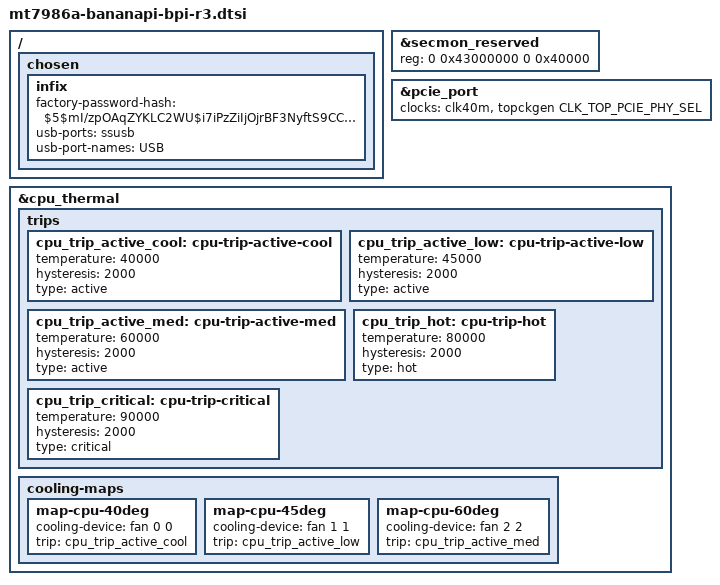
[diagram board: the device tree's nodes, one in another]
/ {
	chosen {
		infix {
			/* Default admin user password: 'admin' */
			factory-password-hash = "$5$mI/zpOAqZYKLC2WU$i7iPzZiIjOjrBF3NyftS9CCq8dfYwHwrmUK097Jca9A";
			usb-ports = <&ssusb>;
			usb-port-names = "USB";
		};
	};
};
/*
From 236317dd4e55512933dcdaec3d0b4a0824f5e5bd Mon Sep 17 00:00:00 2001
From: Shiji Yang <yangshiji66@outlook.com>
Date: Sun, 10 Aug 2025 18:11:01 +0800
Subject: [PATCH] arm64: dts: mediatek: mt7986: increase ATF reserved memory to
 256 kiB

The latest Mediatek open-source Trusted Firmware-A project has
reserved 256 KiB for BL2 and BL31. It is better to increase the
reserved memory region in the Linux kernel to protect the data.

https://github.com/openwrt/openwrt/blob/main/target/linux/mediatek/patches-6.12/199-arm64-dts-mediatek-mt7986-increase-ATF-reserved-memo.patch
*/
&secmon_reserved {
	reg = <0 0x43000000 0 0x40000>;
};
/*
 * The T-PHY's pcie-phy sub-node only claims clk40m ("ref") in the SoC
 * dtsi.  CLK_TOP_PCIE_PHY_SEL ("da_ref") is left unclaimed, so the
 * kernel's clk_disable_unused late_initcall gates it — killing the
 * PCIe REFCLK output to the endpoint mid-probe.  Wire it here so the
 * clock stays enabled while the PHY is active.
 */
&pcie_port {
	clocks = <&clk40m>, <&topckgen CLK_TOP_PCIE_PHY_SEL>;
	clock-names = "ref", "da_ref";
};

&cpu_thermal {
	/delete-node/ trips;
	/delete-node/ cooling-maps;
	trips {
		cpu_trip_active_cool: cpu-trip-active-cool {
			temperature = <40000>;   // 40°C
			hysteresis = <2000>;     // 2°C hysteresis
			type = "active";
		};
		cpu_trip_active_low: cpu-trip-active-low {
			temperature = <45000>;   // 40°C
			hysteresis = <2000>;     // 2°C hysteresis
			type = "active";
		};
		cpu_trip_active_med: cpu-trip-active-med {
			temperature = <60000>;   // 60°C
			hysteresis = <2000>;     // 2°C hysteresis
			type = "active";
		};
		cpu_trip_hot: cpu-trip-hot {
			temperature = <80000>;   // 80°C
			hysteresis = <2000>;     // 2°C hysteresis
			type = "hot";
		};
		cpu_trip_critical: cpu-trip-critical {
			temperature = <90000>;   // 90°C
			hysteresis = <2000>;     // 2°C hysteresis
			type = "critical";
		};
	};

	cooling-maps {
		map-cpu-40deg {
			cooling-device = <&fan 0 0>;
			trip = <&cpu_trip_active_cool>;
		};
		map-cpu-45deg {
			cooling-device = <&fan 1 1>;
			trip = <&cpu_trip_active_low>;
		};
		map-cpu-60deg {
			cooling-device = <&fan 2 2>;
			trip = <&cpu_trip_active_med>;
		};
	};
};
